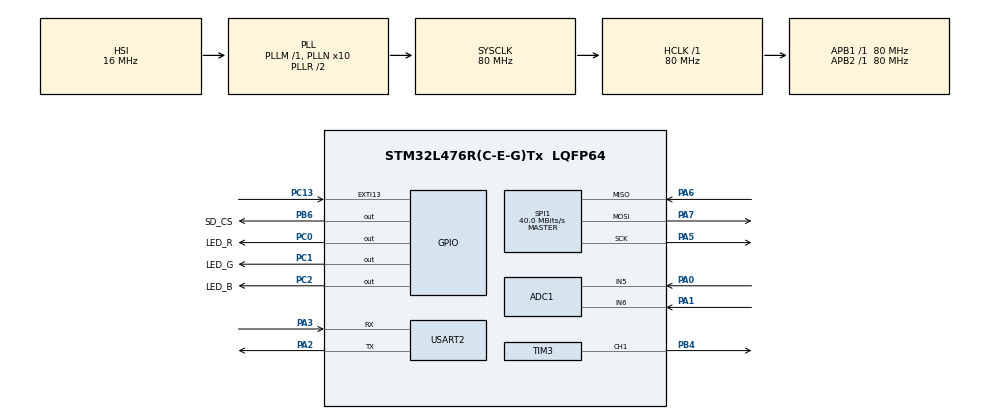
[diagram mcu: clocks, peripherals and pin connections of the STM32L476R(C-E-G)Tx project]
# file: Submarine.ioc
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ADC1.Channel-0\#ChannelRegularConversion=ADC_CHANNEL_5
ADC1.NbrOfConversionFlag=1
ADC1.OffsetNumber-0\#ChannelRegularConversion=ADC_OFFSET_NONE
ADC1.Rank-0\#ChannelRegularConversion=1
ADC1.SamplingTime-0\#ChannelRegularConversion=ADC_SAMPLETIME_2CYCLES_5
ADC1.master=1
FREERTOS.Tasks01=defaultTask,24,128,StartDefaultTask,Default,NULL,Dynamic,NULL,NULL
FREERTOS.configCHECK_FOR_STACK_OVERFLOW=2
FREERTOS.configTOTAL_HEAP_SIZE=15360
FREERTOS.configUSE_NEWLIB_REENTRANT=1
IWDG.Prescaler=IWDG_PRESCALER_32
Mcu.Family=STM32L4
Mcu.Name=STM32L476R(C-E-G)Tx
Mcu.Package=LQFP64
NVIC.EXTI15_10_IRQn=true\:5\:0\:false\:false\:true\:true\:true\:true\:true
NVIC.PriorityGroup=NVIC_PRIORITYGROUP_4
NVIC.TIM6_DAC_IRQn=true\:15\:0\:false\:false\:true\:false\:false\:true\:true
NVIC.TimeBase=TIM6_DAC_IRQn
NVIC.TimeBaseIP=TIM6
NVIC.USART2_IRQn=true\:5\:0\:false\:false\:true\:true\:true\:true\:true
PA0.Signal=ADCx_IN5
PA1.Signal=ADCx_IN6
PA2.Mode=Asynchronous
PA2.Signal=USART2_TX
PA3.Mode=Asynchronous
PA3.Signal=USART2_RX
PA5.Mode=Full_Duplex_Master
PA5.Signal=SPI1_SCK
PA6.Mode=Full_Duplex_Master
PA6.Signal=SPI1_MISO
PA7.Mode=Full_Duplex_Master
PA7.Signal=SPI1_MOSI
PB4\ (NJTRST).Signal=S_TIM3_CH1
PB6.GPIO_Label=SD_CS
PB6.Signal=GPIO_Output
PC0.GPIO_Label=LED_R
PC0.Signal=GPIO_Output
PC1.GPIO_Label=LED_G
PC1.Signal=GPIO_Output
PC13.Signal=GPXTI13
PC2.GPIO_Label=LED_B
PC2.Signal=GPIO_Output
ProjectManager.HeapSize=0x200
ProjectManager.StackSize=0x400
ProjectManager.TargetToolchain=STM32CubeIDE
RCC.ADCFreq_Value=64000000
RCC.AHBFreq_Value=80000000
RCC.APB1Freq_Value=80000000
RCC.APB1TimFreq_Value=80000000
RCC.APB2Freq_Value=80000000
RCC.APB2TimFreq_Value=80000000
RCC.CortexFreq_Value=80000000
RCC.HCLKFreq_Value=80000000
RCC.HSE_VALUE=8000000
RCC.HSI_VALUE=16000000
RCC.LSE_VALUE=32768
RCC.MSI_VALUE=4000000
RCC.PLLN=10
RCC.PLLSourceVirtual=RCC_PLLSOURCE_HSI
RCC.PREFETCH_ENABLE=1
RCC.SYSCLKFreq_VALUE=80000000
RCC.SYSCLKSource=RCC_SYSCLKSOURCE_PLLCLK
RCC.USBFreq_Value=64000000
RCC.VCOOutputFreq_Value=160000000
SH.ADCx_IN5.0=ADC1_IN5,IN5-Single-Ended
SH.ADCx_IN6.0=ADC1_IN6,IN6-Single-Ended
SH.S_TIM3_CH1.0=TIM3_CH1,PWM Generation1 CH1
SPI1.CalculateBaudRate=40.0 MBits/s
SPI1.Direction=SPI_DIRECTION_2LINES
SPI1.Mode=SPI_MODE_MASTER
SPI1.VirtualType=VM_MASTER
TIM3.Channel-PWM\ Generation1\ CH1=TIM_CHANNEL_1
TIM3.Period=999
TIM3.Prescaler=79
TIM5.Period=65535
TIM5.Prescaler=79
USART2.VirtualMode-Asynchronous=VM_ASYNC
VP_FATFS_VS_Generic.Mode=User_defined
VP_FREERTOS_VS_CMSIS_V2.Mode=CMSIS_V2
VP_IWDG_VS_IWDG.Mode=IWDG_Activate
VP_RTC_VS_RTC_Activate.Mode=RTC_Enabled
VP_RTC_VS_RTC_Calendar.Mode=RTC_Calendar
VP_SYS_VS_tim6.Mode=TIM6
VP_TIM5_VS_ClockSourceINT.Mode=Internal
board=NUCLEO-L476RG

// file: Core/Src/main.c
/* USER CODE BEGIN Header */
/**
  ******************************************************************************
  * @file           : main.c
  * @brief          : Main program body
  ******************************************************************************
  * @attention
  *
  * Copyright (c) 2026 STMicroelectronics.
  * All rights reserved.
  *
  * This software is licensed under terms that can be found in the LICENSE file
  * in the root directory of this software component.
  * If no LICENSE file comes with this software, it is provided AS-IS.
  *
  ******************************************************************************
  */
/* USER CODE END Header */
#include "main.h"
#include "cmsis_os.h"
#include "fatfs.h"

/* USER CODE BEGIN Includes */
#include "lnc_app.h"
/* USER CODE END Includes */

ADC_HandleTypeDef hadc1;

IWDG_HandleTypeDef hiwdg;

RTC_HandleTypeDef hrtc;

SPI_HandleTypeDef hspi1;

TIM_HandleTypeDef htim3;
TIM_HandleTypeDef htim5;

UART_HandleTypeDef huart2;

/* Definitions for defaultTask */
osThreadId_t defaultTaskHandle;
const osThreadAttr_t defaultTask_attributes = {
  .name = "defaultTask",
  .stack_size = 128 * 4,
  .priority = (osPriority_t) osPriorityNormal,
};

void SystemClock_Config(void);
static void MX_GPIO_Init(void);
static void MX_USART2_UART_Init(void);
static void MX_IWDG_Init(void);
static void MX_RTC_Init(void);
static void MX_SPI1_Init(void);
static void MX_TIM3_Init(void);
static void MX_TIM5_Init(void);
static void MX_ADC1_Init(void);
void StartDefaultTask(void *argument);

int main(void)
{

  /* MCU Configuration--------------------------------------------------------*/

  /* Reset of all peripherals, Initializes the Flash interface and the Systick. */
  HAL_Init();

  /* Configure the system clock */
  SystemClock_Config();

  /* Initialize all configured peripherals */
  MX_GPIO_Init();
  MX_USART2_UART_Init();
  MX_IWDG_Init();
  MX_RTC_Init();
  MX_SPI1_Init();
  MX_TIM3_Init();
  MX_TIM5_Init();
  MX_FATFS_Init();
  MX_ADC1_Init();
  /* USER CODE BEGIN 2 */
  lnc_app_init();
  /* USER CODE END 2 */

  /* Init scheduler */
  osKernelInitialize();

  /* Create the thread(s) */
  /* creation of defaultTask */
  defaultTaskHandle = osThreadNew(StartDefaultTask, NULL, &defaultTask_attributes);

  /* Start scheduler */
  osKernelStart();

  /* We should never get here as control is now taken by the scheduler */

  /* Infinite loop */
  while (1)
  {

    /* USER CODE BEGIN 3 */
    /* Unreached: the FreeRTOS scheduler owns execution after osKernelStart(). */
  }
  /* USER CODE END 3 */
}

void SystemClock_Config(void)
{
  RCC_OscInitTypeDef RCC_OscInitStruct = {0};
  RCC_ClkInitTypeDef RCC_ClkInitStruct = {0};

  /** Configure the main internal regulator output voltage
  */
  if (HAL_PWREx_ControlVoltageScaling(PWR_REGULATOR_VOLTAGE_SCALE1) != HAL_OK)
  {
    Error_Handler();
  }

  /** Initializes the RCC Oscillators according to the specified parameters
  * in the RCC_OscInitTypeDef structure.
  */
  RCC_OscInitStruct.OscillatorType = RCC_OSCILLATORTYPE_HSI|RCC_OSCILLATORTYPE_LSI;
  RCC_OscInitStruct.HSIState = RCC_HSI_ON;
  RCC_OscInitStruct.HSICalibrationValue = RCC_HSICALIBRATION_DEFAULT;
  RCC_OscInitStruct.LSIState = RCC_LSI_ON;
  RCC_OscInitStruct.PLL.PLLState = RCC_PLL_ON;
  RCC_OscInitStruct.PLL.PLLSource = RCC_PLLSOURCE_HSI;
  RCC_OscInitStruct.PLL.PLLM = 1;
  RCC_OscInitStruct.PLL.PLLN = 10;
  RCC_OscInitStruct.PLL.PLLP = RCC_PLLP_DIV7;
  RCC_OscInitStruct.PLL.PLLQ = RCC_PLLQ_DIV2;
  RCC_OscInitStruct.PLL.PLLR = RCC_PLLR_DIV2;
  if (HAL_RCC_OscConfig(&RCC_OscInitStruct) != HAL_OK)
  {
    Error_Handler();
  }

  /** Initializes the CPU, AHB and APB buses clocks
  */
  RCC_ClkInitStruct.ClockType = RCC_CLOCKTYPE_HCLK|RCC_CLOCKTYPE_SYSCLK
                              |RCC_CLOCKTYPE_PCLK1|RCC_CLOCKTYPE_PCLK2;
  RCC_ClkInitStruct.SYSCLKSource = RCC_SYSCLKSOURCE_PLLCLK;
  RCC_ClkInitStruct.AHBCLKDivider = RCC_SYSCLK_DIV1;
  RCC_ClkInitStruct.APB1CLKDivider = RCC_HCLK_DIV1;
  RCC_ClkInitStruct.APB2CLKDivider = RCC_HCLK_DIV1;

  if (HAL_RCC_ClockConfig(&RCC_ClkInitStruct, FLASH_LATENCY_4) != HAL_OK)
  {
    Error_Handler();
  }
}

static void MX_ADC1_Init(void)
{

  ADC_MultiModeTypeDef multimode = {0};
  ADC_ChannelConfTypeDef sConfig = {0};

  /** Common config
  */
  hadc1.Instance = ADC1;
  hadc1.Init.ClockPrescaler = ADC_CLOCK_ASYNC_DIV1;
  hadc1.Init.Resolution = ADC_RESOLUTION_12B;
  hadc1.Init.DataAlign = ADC_DATAALIGN_RIGHT;
  hadc1.Init.ScanConvMode = ADC_SCAN_DISABLE;
  hadc1.Init.EOCSelection = ADC_EOC_SINGLE_CONV;
  hadc1.Init.LowPowerAutoWait = DISABLE;
  hadc1.Init.ContinuousConvMode = DISABLE;
  hadc1.Init.NbrOfConversion = 1;
  hadc1.Init.DiscontinuousConvMode = DISABLE;
  hadc1.Init.ExternalTrigConv = ADC_SOFTWARE_START;
  hadc1.Init.ExternalTrigConvEdge = ADC_EXTERNALTRIGCONVEDGE_NONE;
  hadc1.Init.DMAContinuousRequests = DISABLE;
  hadc1.Init.Overrun = ADC_OVR_DATA_PRESERVED;
  hadc1.Init.OversamplingMode = DISABLE;
  if (HAL_ADC_Init(&hadc1) != HAL_OK)
  {
    Error_Handler();
  }

  /** Configure the ADC multi-mode
  */
  multimode.Mode = ADC_MODE_INDEPENDENT;
  if (HAL_ADCEx_MultiModeConfigChannel(&hadc1, &multimode) != HAL_OK)
  {
    Error_Handler();
  }

  /** Configure Regular Channel
  */
  sConfig.Channel = ADC_CHANNEL_5;
  sConfig.Rank = ADC_REGULAR_RANK_1;
  sConfig.SamplingTime = ADC_SAMPLETIME_2CYCLES_5;
  sConfig.SingleDiff = ADC_SINGLE_ENDED;
  sConfig.OffsetNumber = ADC_OFFSET_NONE;
  sConfig.Offset = 0;
  if (HAL_ADC_ConfigChannel(&hadc1, &sConfig) != HAL_OK)
  {
    Error_Handler();
  }

}

static void MX_IWDG_Init(void)
{

  hiwdg.Instance = IWDG;
  hiwdg.Init.Prescaler = IWDG_PRESCALER_32;
  hiwdg.Init.Window = 4095;
  hiwdg.Init.Reload = 4095;
  if (HAL_IWDG_Init(&hiwdg) != HAL_OK)
  {
    Error_Handler();
  }

}

static void MX_RTC_Init(void)
{

  RTC_TimeTypeDef sTime = {0};
  RTC_DateTypeDef sDate = {0};

  /** Initialize RTC Only
  */
  hrtc.Instance = RTC;
  hrtc.Init.HourFormat = RTC_HOURFORMAT_24;
  hrtc.Init.AsynchPrediv = 127;
  hrtc.Init.SynchPrediv = 255;
  hrtc.Init.OutPut = RTC_OUTPUT_DISABLE;
  hrtc.Init.OutPutRemap = RTC_OUTPUT_REMAP_NONE;
  hrtc.Init.OutPutPolarity = RTC_OUTPUT_POLARITY_HIGH;
  hrtc.Init.OutPutType = RTC_OUTPUT_TYPE_OPENDRAIN;
  if (HAL_RTC_Init(&hrtc) != HAL_OK)
  {
    Error_Handler();
  }

  /** Initialize RTC and set the Time and Date
  */
  sTime.Hours = 0x0;
  sTime.Minutes = 0x0;
  sTime.Seconds = 0x0;
  sTime.DayLightSaving = RTC_DAYLIGHTSAVING_NONE;
  sTime.StoreOperation = RTC_STOREOPERATION_RESET;
  if (HAL_RTC_SetTime(&hrtc, &sTime, RTC_FORMAT_BCD) != HAL_OK)
  {
    Error_Handler();
  }
  sDate.WeekDay = RTC_WEEKDAY_MONDAY;
  sDate.Month = RTC_MONTH_JANUARY;
  sDate.Date = 0x1;
  sDate.Year = 0x0;

  if (HAL_RTC_SetDate(&hrtc, &sDate, RTC_FORMAT_BCD) != HAL_OK)
  {
    Error_Handler();
  }

}

static void MX_SPI1_Init(void)
{

  /* SPI1 parameter configuration*/
  hspi1.Instance = SPI1;
  hspi1.Init.Mode = SPI_MODE_MASTER;
  hspi1.Init.Direction = SPI_DIRECTION_2LINES;
  hspi1.Init.DataSize = SPI_DATASIZE_4BIT;
  hspi1.Init.CLKPolarity = SPI_POLARITY_LOW;
  hspi1.Init.CLKPhase = SPI_PHASE_1EDGE;
  hspi1.Init.NSS = SPI_NSS_SOFT;
  hspi1.Init.BaudRatePrescaler = SPI_BAUDRATEPRESCALER_2;
  hspi1.Init.FirstBit = SPI_FIRSTBIT_MSB;
  hspi1.Init.TIMode = SPI_TIMODE_DISABLE;
  hspi1.Init.CRCCalculation = SPI_CRCCALCULATION_DISABLE;
  hspi1.Init.CRCPolynomial = 7;
  hspi1.Init.CRCLength = SPI_CRC_LENGTH_DATASIZE;
  hspi1.Init.NSSPMode = SPI_NSS_PULSE_ENABLE;
  if (HAL_SPI_Init(&hspi1) != HAL_OK)
  {
    Error_Handler();
  }

}

static void MX_TIM3_Init(void)
{

  TIM_MasterConfigTypeDef sMasterConfig = {0};
  TIM_OC_InitTypeDef sConfigOC = {0};

  htim3.Instance = TIM3;
  htim3.Init.Prescaler = 79;
  htim3.Init.CounterMode = TIM_COUNTERMODE_UP;
  htim3.Init.Period = 999;
  htim3.Init.ClockDivision = TIM_CLOCKDIVISION_DIV1;
  htim3.Init.AutoReloadPreload = TIM_AUTORELOAD_PRELOAD_DISABLE;
  if (HAL_TIM_PWM_Init(&htim3) != HAL_OK)
  {
    Error_Handler();
  }
  sMasterConfig.MasterOutputTrigger = TIM_TRGO_RESET;
  sMasterConfig.MasterSlaveMode = TIM_MASTERSLAVEMODE_DISABLE;
  if (HAL_TIMEx_MasterConfigSynchronization(&htim3, &sMasterConfig) != HAL_OK)
  {
    Error_Handler();
  }
  sConfigOC.OCMode = TIM_OCMODE_PWM1;
  sConfigOC.Pulse = 0;
  sConfigOC.OCPolarity = TIM_OCPOLARITY_HIGH;
  sConfigOC.OCFastMode = TIM_OCFAST_DISABLE;
  if (HAL_TIM_PWM_ConfigChannel(&htim3, &sConfigOC, TIM_CHANNEL_1) != HAL_OK)
  {
    Error_Handler();
  }
  HAL_TIM_MspPostInit(&htim3);

}

static void MX_TIM5_Init(void)
{

  TIM_ClockConfigTypeDef sClockSourceConfig = {0};
  TIM_MasterConfigTypeDef sMasterConfig = {0};

  htim5.Instance = TIM5;
  htim5.Init.Prescaler = 79;
  htim5.Init.CounterMode = TIM_COUNTERMODE_UP;
  htim5.Init.Period = 65535;
  htim5.Init.ClockDivision = TIM_CLOCKDIVISION_DIV1;
  htim5.Init.AutoReloadPreload = TIM_AUTORELOAD_PRELOAD_DISABLE;
  if (HAL_TIM_Base_Init(&htim5) != HAL_OK)
  {
    Error_Handler();
  }
  sClockSourceConfig.ClockSource = TIM_CLOCKSOURCE_INTERNAL;
  if (HAL_TIM_ConfigClockSource(&htim5, &sClockSourceConfig) != HAL_OK)
  {
    Error_Handler();
  }
  sMasterConfig.MasterOutputTrigger = TIM_TRGO_RESET;
  sMasterConfig.MasterSlaveMode = TIM_MASTERSLAVEMODE_DISABLE;
  if (HAL_TIMEx_MasterConfigSynchronization(&htim5, &sMasterConfig) != HAL_OK)
  {
    Error_Handler();
  }

}

static void MX_USART2_UART_Init(void)
{

  huart2.Instance = USART2;
  huart2.Init.BaudRate = 115200;
  huart2.Init.WordLength = UART_WORDLENGTH_8B;
  huart2.Init.StopBits = UART_STOPBITS_1;
  huart2.Init.Parity = UART_PARITY_NONE;
  huart2.Init.Mode = UART_MODE_TX_RX;
  huart2.Init.HwFlowCtl = UART_HWCONTROL_NONE;
  huart2.Init.OverSampling = UART_OVERSAMPLING_16;
  huart2.Init.OneBitSampling = UART_ONE_BIT_SAMPLE_DISABLE;
  huart2.AdvancedInit.AdvFeatureInit = UART_ADVFEATURE_NO_INIT;
  if (HAL_UART_Init(&huart2) != HAL_OK)
  {
    Error_Handler();
  }

}

static void MX_GPIO_Init(void)
{
  GPIO_InitTypeDef GPIO_InitStruct = {0};

  /* GPIO Ports Clock Enable */
  __HAL_RCC_GPIOC_CLK_ENABLE();
  __HAL_RCC_GPIOA_CLK_ENABLE();
  __HAL_RCC_GPIOB_CLK_ENABLE();

  /*Configure GPIO pin Output Level */
  HAL_GPIO_WritePin(GPIOC, LED_R_Pin|LED_G_Pin|LED_B_Pin, GPIO_PIN_RESET);

  /*Configure GPIO pin Output Level */
  HAL_GPIO_WritePin(SD_CS_GPIO_Port, SD_CS_Pin, GPIO_PIN_RESET);

  /*Configure GPIO pin : PC13 */
  GPIO_InitStruct.Pin = GPIO_PIN_13;
  GPIO_InitStruct.Mode = GPIO_MODE_IT_RISING;
  GPIO_InitStruct.Pull = GPIO_NOPULL;
  HAL_GPIO_Init(GPIOC, &GPIO_InitStruct);

  /*Configure GPIO pins : LED_R_Pin LED_G_Pin LED_B_Pin */
  GPIO_InitStruct.Pin = LED_R_Pin|LED_G_Pin|LED_B_Pin;
  GPIO_InitStruct.Mode = GPIO_MODE_OUTPUT_PP;
  GPIO_InitStruct.Pull = GPIO_NOPULL;
  GPIO_InitStruct.Speed = GPIO_SPEED_FREQ_LOW;
  HAL_GPIO_Init(GPIOC, &GPIO_InitStruct);

  /*Configure GPIO pin : SD_CS_Pin */
  GPIO_InitStruct.Pin = SD_CS_Pin;
  GPIO_InitStruct.Mode = GPIO_MODE_OUTPUT_PP;
  GPIO_InitStruct.Pull = GPIO_NOPULL;
  GPIO_InitStruct.Speed = GPIO_SPEED_FREQ_LOW;
  HAL_GPIO_Init(SD_CS_GPIO_Port, &GPIO_InitStruct);

  /* EXTI interrupt init*/
  HAL_NVIC_SetPriority(EXTI15_10_IRQn, 5, 0);
  HAL_NVIC_EnableIRQ(EXTI15_10_IRQn);

}

void StartDefaultTask(void *argument)
{
  /* USER CODE BEGIN 5 */
  lnc_app_start();                 /* create queues, mutexes, and the worker tasks */
  /* This default task becomes the Watchdog module (spec §2.9). */
  for(;;)
  {
    lnc_app_watchdog_step();       /* supervised IWDG refresh */
    osDelay(250);
  }
  /* USER CODE END 5 */
}

void HAL_TIM_PeriodElapsedCallback(TIM_HandleTypeDef *htim)
{
  if (htim->Instance == TIM6)
  {
    HAL_IncTick();
  }
}

void Error_Handler(void)
{
  __disable_irq();
  while (1)
  {
  }
}
